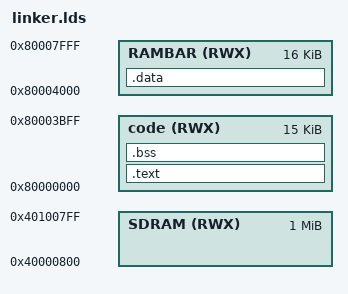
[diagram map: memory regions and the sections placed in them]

ENTRY(_start)

MEMORY
{
        /* vectorarea (RWX) : ORIGIN = 0x80000000, LENGTH = 0x00000400 */
        code   (RWX) : ORIGIN = 0x80000000, LENGTH = 0x00003C00
        SDRAM  (RWX) : ORIGIN = 0x40000800, LENGTH = 0x00100000 /* 32M - 0x800 */
        RAMBAR (RWX) : ORIGIN = 0x80004000, LENGTH = 0x00004000
}

SECTIONS
{
        /**********************************************************************
         *                                                                    *
         **********************************************************************/
        /* dummy initializations
        .vectorarea: { } > vectorarea
        .code:       { } > code
        .sdram:      { } > sdram */
        /**********************************************************************
         *                                                                    *
         **********************************************************************/
        /* .vectors :
        {
                *(.vectors)
                . = ALIGN (0x10);
        } > code */
        /**********************************************************************
         *                                                                    *
         **********************************************************************/
        .text :
        {
                *(.vectors)
                *(.text)
                *(.text.*)
                *(.rodata)
                *(.rodata.*)
                . = ALIGN (0x10);
        } > code
        /**********************************************************************
         *                                                                    *
         **********************************************************************/
        .data :
        {
                *(.data)
                *(.data.*)
                . = ALIGN (0x10);
                *(.sdata)
                . = ALIGN (0x10);
                __SDA_BASE = .;
                . = ALIGN (0x10);
        } > RAMBAR
        /**********************************************************************
         *                                                                    *
         **********************************************************************/
        .bss :
        {
                *(.bss)
                *(.bss.*)
                *(COMMON)
                . = ALIGN (0x10);
        } > code
        /**********************************************************************
         *                                                                    *
         **********************************************************************/
        .debug_info     : { *(.debug_info) }
        .debug_abbrev   : { *(.debug_abbrev) }
        .debug_aranges  : { *(.debug_aranges) }
        .debug_frame    : { *(.debug_frame) }
        .debug_line     : { *(.debug_line) }
        .debug_line_str : { *(.debug_line_str) }
        .debug_loclists : { *(.debug_loclists) }
        .debug_macro    : { *(.debug_macro) }
        .debug_names    : { *(.debug_names) }
        .debug_rnglists : { *(.debug_rnglists) }
        .debug_str      : { *(.debug_str) }
        /**********************************************************************
         *                                                                    *
         **********************************************************************/
        /DISCARD/ :
        {
                *(.comment)
        }
}

